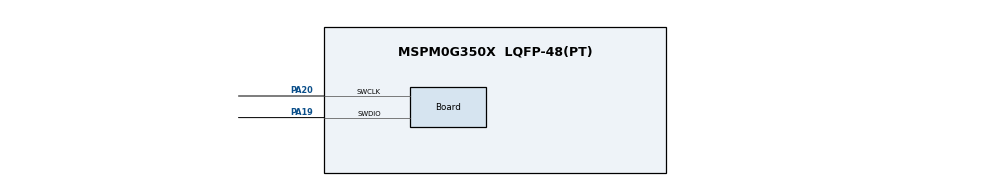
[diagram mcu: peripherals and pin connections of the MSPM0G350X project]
/**
 * @cliArgs --device "MSPM0G350X" --part "Default" --package "LQFP-48(PT)" --product "mspm0_sdk@2.04.00.06"
 * @versions {"tool":"1.22.0+3893"}
 */

/**
 * Import the modules used in this configuration.
 */
const Board   = scripting.addModule("/ti/driverlib/Board");
const GPIO    = scripting.addModule("/ti/driverlib/GPIO", {}, false);
const GPIO1   = GPIO.addInstance();
const GPIO2   = GPIO.addInstance();
const SYSCTL  = scripting.addModule("/ti/driverlib/SYSCTL");
const SYSTICK = scripting.addModule("/ti/driverlib/SYSTICK");
const UART    = scripting.addModule("/ti/driverlib/UART", {}, false);
const UART1   = UART.addInstance();

/**
 * Write custom configuration values to the imported modules.
 */
Board.peripheral.$assign          = "DEBUGSS";
Board.peripheral.swclkPin.$assign = "PA20";
Board.peripheral.swdioPin.$assign = "PA19";

GPIO1.$name                          = "BSL";
GPIO1.associatedPins[0].$name        = "PIN_18";
GPIO1.associatedPins[0].assignedPin  = "18";
GPIO1.associatedPins[0].assignedPort = "PORTA";

GPIO2.$name                              = "GPIO";
GPIO2.associatedPins.create(2);
GPIO2.associatedPins[0].$name            = "SDA";
GPIO2.associatedPins[0].internalResistor = "PULL_UP";
GPIO2.associatedPins[0].assignedPort     = "PORTA";
GPIO2.associatedPins[0].assignedPin      = "28";
GPIO2.associatedPins[1].$name            = "SCL";
GPIO2.associatedPins[1].assignedPort     = "PORTA";
GPIO2.associatedPins[1].assignedPin      = "31";
GPIO2.associatedPins[1].internalResistor = "PULL_UP";

SYSCTL.forceDefaultClkConfig = true;
SYSCTL.peripheral.$assign    = "SYSCTL";

SYSTICK.periodEnable      = true;
SYSTICK.period            = 32000;
SYSTICK.interruptEnable   = true;
SYSTICK.systickEnable     = true;
SYSTICK.interruptPriority = "0";

UART1.enabledInterrupts                = ["RX"];
UART1.$name                            = "HC06";
UART1.peripheral.$assign               = "UART2";
UART1.txPinConfig.direction            = scripting.forceWrite("OUTPUT");
UART1.txPinConfig.hideOutputInversion  = scripting.forceWrite(false);
UART1.txPinConfig.onlyInternalResistor = scripting.forceWrite(false);
UART1.txPinConfig.passedPeripheralType = scripting.forceWrite("Digital");
UART1.txPinConfig.$name                = "ti_driverlib_gpio_GPIOPinGeneric0";
UART1.rxPinConfig.hideOutputInversion  = scripting.forceWrite(false);
UART1.rxPinConfig.onlyInternalResistor = scripting.forceWrite(false);
UART1.rxPinConfig.passedPeripheralType = scripting.forceWrite("Digital");
UART1.rxPinConfig.$name                = "ti_driverlib_gpio_GPIOPinGeneric1";

const ProjectConfig              = scripting.addModule("/ti/project_config/ProjectConfig", {}, false);
ProjectConfig.migrationCondition = true;

/**
 * Pinmux solution for unlocked pins/peripherals. This ensures that minor changes to the automatic solver in a future
 * version of the tool will not impact the pinmux you originally saw.  These lines can be completely deleted in order to
 * re-solve from scratch.
 */
GPIO1.associatedPins[0].pin.$suggestSolution = "PA18";
GPIO2.associatedPins[0].pin.$suggestSolution = "PA28";
GPIO2.associatedPins[1].pin.$suggestSolution = "PA31";
UART1.peripheral.rxPin.$suggestSolution      = "PA22";
UART1.peripheral.txPin.$suggestSolution      = "PA21";
